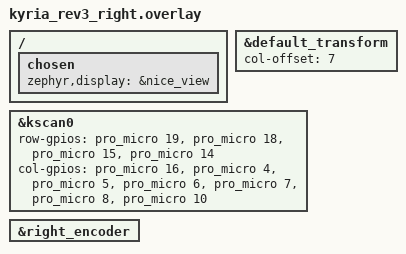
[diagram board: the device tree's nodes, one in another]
/*
 * Copyright (c) 2023 The ZMK Contributors
 *
 * SPDX-License-Identifier: MIT
 */

#include "kyria_rev3.dtsi"

&default_transform {
    col-offset = <7>;
};

&kscan0 {
    row-gpios
    = <&pro_micro 19 (GPIO_ACTIVE_HIGH | GPIO_PULL_DOWN)>
    , <&pro_micro 18 (GPIO_ACTIVE_HIGH | GPIO_PULL_DOWN)>
    , <&pro_micro 15 (GPIO_ACTIVE_HIGH | GPIO_PULL_DOWN)>
    , <&pro_micro 14 (GPIO_ACTIVE_HIGH | GPIO_PULL_DOWN)>
    ;
    col-gpios
    = <&pro_micro 16 GPIO_ACTIVE_HIGH>
    , <&pro_micro 4  GPIO_ACTIVE_HIGH>
    , <&pro_micro 5  GPIO_ACTIVE_HIGH>
    , <&pro_micro 6  GPIO_ACTIVE_HIGH>
    , <&pro_micro 7  GPIO_ACTIVE_HIGH>
    , <&pro_micro 8  GPIO_ACTIVE_HIGH>
    , <&pro_micro 10 GPIO_ACTIVE_HIGH>
    ;
};

&right_encoder {
    status = "okay";
};
/* ── nice!view (right half) ──────────────────────────────────────────────
 * Wiring identical to the left half:
 *   VCC/GND -> OLED socket, CS -> D1 (P0.06), MOSI -> D2 (P0.17),
 *   SCL -> D9 (P1.06).  D3 (adapter default) conflicts with the matrix.
 */
/* The kyria board overlay (kyria/boards/nice_nano_nrf52840_zmk.overlay)
 * re-points chosen zephyr,display at the (now disabled) SSD1306. Re-assert
 * nice!view here: user config overlays load after all shield overlays.
 */
/ {
    chosen {
        zephyr,display = &nice_view;
    };
};
